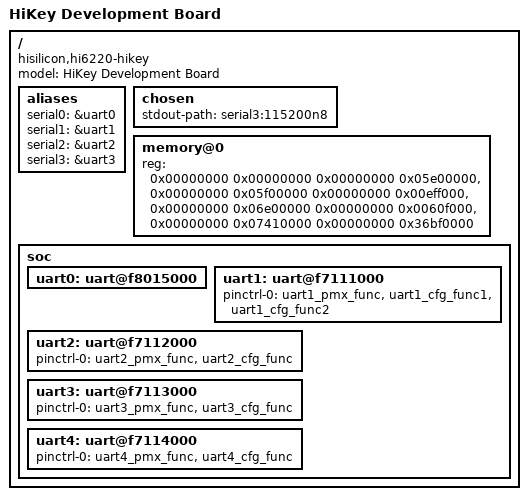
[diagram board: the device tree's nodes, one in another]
/*
 * dts file for Hisilicon HiKey Development Board
 *
 * Copyright (C) 2015, Hisilicon Ltd.
 *
 */

/dts-v1/;

#include "hikey-gpio.dtsi"
#include "hikey-pinctrl.dtsi"
#include "hi6220.dtsi"

/ {
	model = "HiKey Development Board";
	compatible = "hisilicon,hi6220-hikey", "hisilicon,hi6220";

	aliases {
		serial0 = &uart0; /* On board UART0 */
		serial1 = &uart1; /* BT UART */
		serial2 = &uart2; /* LS Expansion UART0 */
		serial3 = &uart3; /* LS Expansion UART1 */
	};

	chosen {
		stdout-path = "serial3:115200n8";
	};

	/*
	 * Reserve below regions from memory node:
	 *
	 *  - 0x05e0,0000 - 0x05ef,ffff: MCU firmware runtime using
	 *  - 0x06df,f000 - 0x06df,ffff: Mailbox message data
	 *  - 0x0740,f000 - 0x0740,ffff: MCU firmware section
	 *  - 0x3e00,0000 - 0x3fff,ffff: OP-TEE
	 */
	memory@0 {
		device_type = "memory";
		reg = <0x00000000 0x00000000 0x00000000 0x05e00000>,
		      <0x00000000 0x05f00000 0x00000000 0x00eff000>,
		      <0x00000000 0x06e00000 0x00000000 0x0060f000>,
		      <0x00000000 0x07410000 0x00000000 0x36bf0000>;
	};

	soc {
		uart0: uart@f8015000 {
			status = "ok";
		};

		uart1: uart@f7111000 {
			pinctrl-names = "default";
			pinctrl-0 = <&uart1_pmx_func
					&uart1_cfg_func1 &uart1_cfg_func2>;
			status = "ok";
		};

		uart2: uart@f7112000 {
			pinctrl-names = "default";
			pinctrl-0 = <&uart2_pmx_func &uart2_cfg_func>;
			status = "ok";
		};

		uart3: uart@f7113000 {
			pinctrl-names = "default";
			pinctrl-0 = <&uart3_pmx_func &uart3_cfg_func>;
			status = "ok";
		};

		uart4: uart@f7114000 {
			pinctrl-names = "default";
			pinctrl-0 = <&uart4_pmx_func &uart4_cfg_func>;
			status = "ok";
		};
	};
};
